VERSION ""

NS_ :

BS_: 500

BU_: Vector__XXX

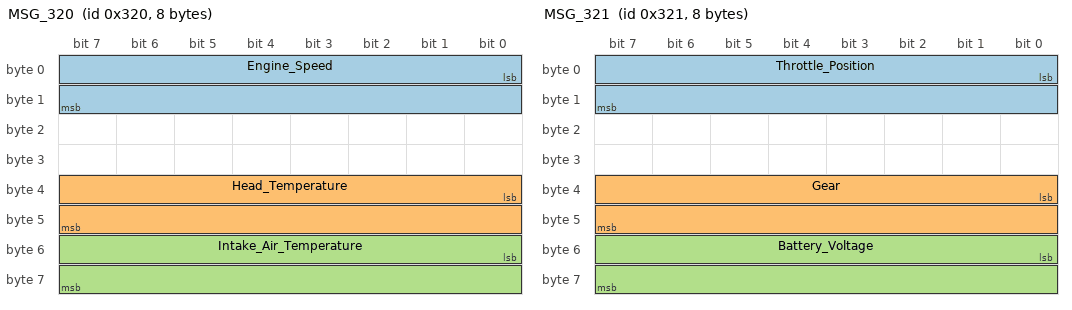
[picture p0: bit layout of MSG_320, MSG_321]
BO_ 800 MSG_320: 8 Vector__XXX
 SG_ Engine_Speed : 0|16@1+ (1,0) [0|30000] "rpm" Vector__XXX
 SG_ Head_Temperature : 32|16@1+ (0.1,-50) [-50|250] "��C" Vector__XXX
 SG_ Intake_Air_Temperature : 48|16@1+ (0.1,-50) [-50|250] "��C" Vector__XXX

BO_ 801 MSG_321: 8 Vector__XXX
 SG_ Throttle_Position : 0|16@1+ (0.1,-100) [-100|100] "%" Vector__XXX
 SG_ Gear : 32|16@1+ (1,0) [0|255] "" Vector__XXX
 SG_ Battery_Voltage : 48|16@1+ (0.001,0) [0|20] "V" Vector__XXX

BO_ 802 MSG_322: 8 Vector__XXX
 SG_ Oil_Temperature : 16|16@1+ (0.1,-50) [-50|250] "��C" Vector__XXX
 SG_ Fuel_Temperature : 48|16@1+ (0.1,-50) [-50|250] "��C" Vector__XXX
